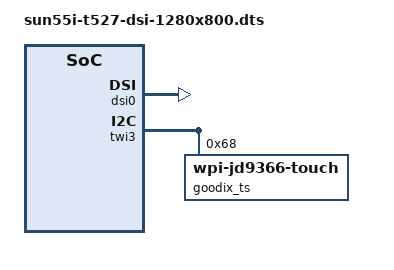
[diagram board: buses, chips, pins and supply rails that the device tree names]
/dts-v1/;
/plugin/;

/ {
	fragment@0 {
		target-path = "/";
		__overlay__ {
			panel_dsi: panel_dsi {
				power0-supply = <&reg_dcdc4>;
				status = "okay";
				backlight = <&backlight0>;
				dsi,flags = <1>;
				dsi,lanes = <2>;
				dsi,format = <0>;
				
				panel-init-sequence = [
				39 00 02 30 01
				39 00 05 78 49 61 02 00

				39 00 02 30 02
				39 00 02 31 12
				39 00 02 32 08
				39 00 02 33 3F
				39 00 02 3C 04
				39 00 02 3D 78
				39 00 02 3E 43
				39 00 02 3F 30
				39 00 02 42 A2
				39 00 02 43 F0
				39 00 02 44 01
				39 00 02 46 17
				39 00 02 49 C0
				39 00 02 6D 30
				39 00 02 6E 21
				39 00 0D 41 5B 5B 03 03 5B 5B 02 02 03 03 03 03
				39 00 0C 5A 00 00 34 34 31 31 23 23 24 24 23
				39 00 0C 5B 23 0B 0B 09 09 0F 0F 0D 0D 06 06
				39 00 0C 5C 00 00 34 34 31 31 23 23 24 24 23
				39 00 0C 5D 23 0A 0A 08 08 0E 0E 0C 0C 05 05
				39 00 0C 5E 00 00 31 31 34 34 23 23 24 24 23
				39 00 0C 5F 23 0C 0C 0E 0E 08 08 0A 0A 05 05
				39 00 0C 60 00 00 31 31 34 34 23 23 24 24 23
				39 00 0C 61 23 0D 0D 0F 0F 09 09 0B 0B 06 06
				39 00 04 64 FF FF 3F
				39 00 04 65 FF FF 3F
				39 00 04 6F 03 00 00
				39 00 04 70 03 00 00
				39 00 04 71 00 00 80
				39 00 04 72 00 00 00
				39 00 03 4C 22 22
				39 00 02 73 2A
				39 00 03 4E 00 00
				39 00 03 50 00 00
				39 00 03 55 FF FF
				39 00 03 56 FF FF
				39 00 03 57 00 00
				39 00 03 58 FF FF
				39 00 03 66 FF FF
				39 00 03 67 FF FF
				39 00 02 4A 3F

				39 00 02 30 08
				39 00 02 31 65
				39 00 02 33 05
				39 00 02 40 50
				39 00 02 41 80
				39 00 02 42 1A
				39 00 02 47 0A
				39 00 02 48 0D
				39 00 02 50 17
				39 00 02 5A 20
				39 00 02 5B 00
				39 00 02 5C 53
				39 00 02 5D 0D
				39 00 02 5F 01
				39 00 02 62 04
				39 00 02 65 5F
				39 00 02 73 01

				39 00 02 30 0A
				39 00 02 32 FF
				39 00 02 33 28
				39 00 02 3F 53
				39 00 02 40 15
				39 00 02 47 20
				39 00 02 48 80
				39 00 02 49 03

				39 00 02 30 0B
				39 00 03 33 00 3D
				39 00 03 3C 00 BF
				39 00 02 43 B1
				39 00 02 44 31
				39 00 06 3E 00 10 1E 27 2F
				39 00 0F 3F 54 6F 73 7C 77 91 90 99 A8 A5 AE B5 C5 B8
				39 00 0A 40 52 52 53 7F 00 10 1E 27 2F
				39 00 0F 41 54 6F 73 7C 77 91 98 99 A8 A5 AE B5 C5 B8
				39 00 05 42 52 52 53 7F
				39 00 02 45 70
				39 00 02 46 3B
				39 00 02 48 7C
				39 00 02 49 1E
				39 00 02 4A 3A

				39 00 02 30 0C
				39 00 02 32 62
				39 00 02 71 77

				39 00 02 30 0D
				39 00 02 4C 74

				39 00 02 30 00
				39 00 02 35 00
				39 50 02 11 00
				39 10 02 29 00
				];
				
				panel-exit-sequence = [
				
				];
				
				display-timings {
					native-mode = <&timing0>;
					timing0: timing0 {
						clock-frequency = <76200000>;
						hback-porch = <28>;             // HBP: 28
						hactive = <800>;                // 水平分辨率: 800
						hfront-porch = <40>;            // HFP: 40
						hsync-len = <8>;                // HS: 8
						vback-porch = <20>;             // VBP: 20
						vactive = <1280>;               // 垂直分辨率: 1280
						vfront-porch = <140>;           // VFP: 140
						vsync-len = <8>;     
					};
				};
				
				
			};
		};
	};
	fragment@1 {
		target = <&dsi0>;
		__overlay__ {
			#address-cells = <1>;
			#size-cells = <0>;
			status = "okay";
			
		};
	};
	fragment@2 {
		target = <&twi3>;
		__overlay__ {
			#address-cells = <1>;
			#size-cells = <0>;
			goodix_ts@68 {
				compatible = "wpi-jd9366-touch";
				reg = <0x68>;
				status = "okay";
				touchscreen-size-y = <1280>;
				touchscreen-size-x = <800>;
				report-as-mouse;
			
			}; 
		};
	};
};

